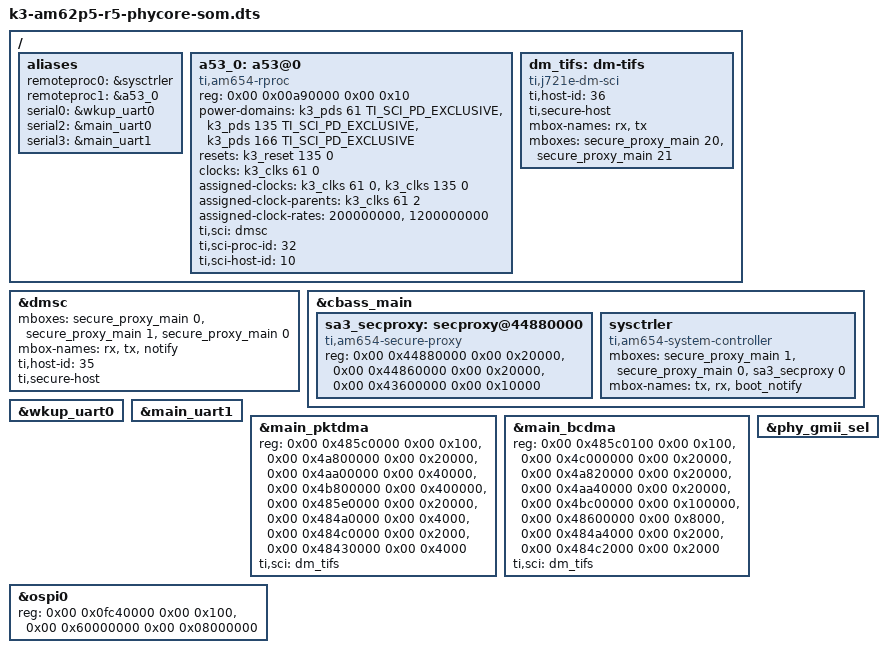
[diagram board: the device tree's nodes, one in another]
// SPDX-License-Identifier: GPL-2.0-only OR MIT
/*
 * phyCORE-AM62Px dts file for R5 SPL
 * Copyright (C) 2025 PHYTEC America LLC
 * Author: John Ma <jma@phytec.com>
 */

#include "k3-am62p5-phyboard-lynx.dts"
#include "k3-am62p5-phyboard-lynx-u-boot.dtsi"

#include "k3-am62p-phycore-som-lpddr4-2gb.dtsi"
#include "k3-am62a-ddr.dtsi"

/ {
	aliases {
		remoteproc0 = &sysctrler;
		remoteproc1 = &a53_0;
		serial0 = &wkup_uart0;
		serial2 = &main_uart0;
		serial3 = &main_uart1;
	};

	a53_0: a53@0 {
		compatible = "ti,am654-rproc";
		reg = <0x00 0x00a90000 0x00 0x10>;
		power-domains = <&k3_pds 61 TI_SCI_PD_EXCLUSIVE>,
			<&k3_pds 135 TI_SCI_PD_EXCLUSIVE>,
			<&k3_pds 166 TI_SCI_PD_EXCLUSIVE>;
		resets = <&k3_reset 135 0>;
		clocks = <&k3_clks 61 0>;
		assigned-clocks = <&k3_clks 61 0>, <&k3_clks 135 0>;
		assigned-clock-parents = <&k3_clks 61 2>;
		assigned-clock-rates = <200000000>, <1200000000>;
		ti,sci = <&dmsc>;
		ti,sci-proc-id = <32>;
		ti,sci-host-id = <10>;
		bootph-all;
	};

	dm_tifs: dm-tifs {
		compatible = "ti,j721e-dm-sci";
		ti,host-id = <36>;
		ti,secure-host;
		mbox-names = "rx", "tx";
		mboxes= <&secure_proxy_main 20>,
			<&secure_proxy_main 21>;
		bootph-all;
	};
};

&dmsc {
	mboxes= <&secure_proxy_main 0>,
		<&secure_proxy_main 1>,
		<&secure_proxy_main 0>;
	mbox-names = "rx", "tx", "notify";
	ti,host-id = <35>;
	ti,secure-host;
	bootph-pre-ram;
};

&cbass_main {
	sa3_secproxy: secproxy@44880000 {
		compatible = "ti,am654-secure-proxy";
		#mbox-cells = <1>;
		reg = <0x00 0x44880000 0x00 0x20000>,
		      <0x00 0x44860000 0x00 0x20000>,
		      <0x00 0x43600000 0x00 0x10000>;
		reg-names = "rt", "scfg", "target_data";
		bootph-all;
	};

	sysctrler: sysctrler {
		compatible = "ti,am654-system-controller";
		mboxes= <&secure_proxy_main 1>,
			<&secure_proxy_main 0>,
			<&sa3_secproxy 0>;
		mbox-names = "tx", "rx", "boot_notify";
		bootph-all;
	};
};

/* WKUP UART0 is used for DM firmware logs */
&wkup_uart0 {
	status = "okay";
};

/* Main UART1 is used for TIFS firmware logs */
&main_uart1 {
	status = "okay";
};

&main_pktdma {
	reg = <0x00 0x485c0000 0x00 0x100>,
	      <0x00 0x4a800000 0x00 0x20000>,
	      <0x00 0x4aa00000 0x00 0x40000>,
	      <0x00 0x4b800000 0x00 0x400000>,
	      <0x00 0x485e0000 0x00 0x20000>,
	      <0x00 0x484a0000 0x00 0x4000>,
	      <0x00 0x484c0000 0x00 0x2000>,
	      <0x00 0x48430000 0x00 0x4000>;
	reg-names = "gcfg", "rchanrt", "tchanrt", "ringrt",
		    "cfg", "tchan", "rchan", "rflow";
	ti,sci = <&dm_tifs>;
	bootph-all;
};

&main_bcdma {
	reg = <0x00 0x485c0100 0x00 0x100>,
	      <0x00 0x4c000000 0x00 0x20000>,
	      <0x00 0x4a820000 0x00 0x20000>,
	      <0x00 0x4aa40000 0x00 0x20000>,
	      <0x00 0x4bc00000 0x00 0x100000>,
	      <0x00 0x48600000 0x00 0x8000>,
	      <0x00 0x484a4000 0x00 0x2000>,
	      <0x00 0x484c2000 0x00 0x2000>;
	reg-names = "gcfg", "bchanrt", "rchanrt", "tchanrt",
		    "ringrt", "cfg", "tchan", "rchan";
	ti,sci = <&dm_tifs>;
};

&ospi0 {
	reg = <0x00 0x0fc40000 0x00 0x100>,
	      <0x00 0x60000000 0x00 0x08000000>;
};

&phy_gmii_sel {
	bootph-all;
};
